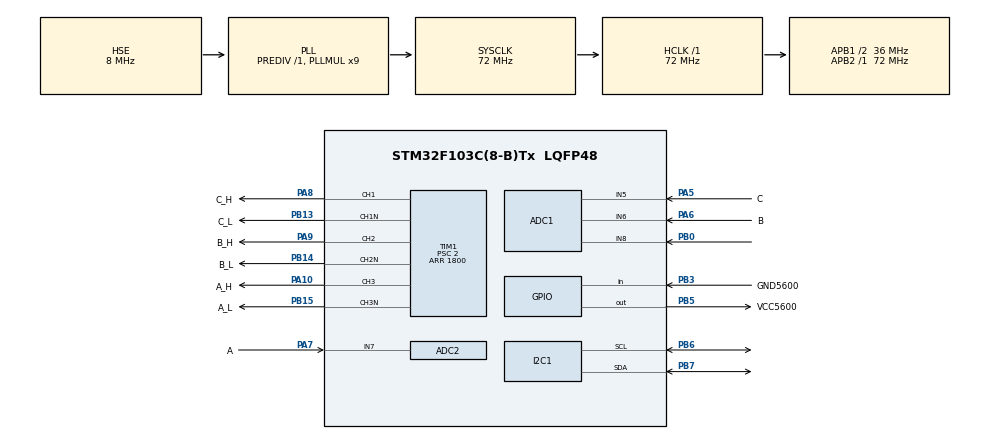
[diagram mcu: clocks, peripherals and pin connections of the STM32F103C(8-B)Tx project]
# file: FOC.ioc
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ADC1.Channel-2\#ChannelInjectedConversion=ADC_CHANNEL_5
ADC1.EnableInjectedConversion=ENABLE
ADC1.EnableRegularConversion=DISABLE
ADC1.ExternalTrigInjecConv=ADC_EXTERNALTRIGINJECCONV_T1_TRGO
ADC1.InjNumberOfConversion=1
ADC1.InjectedOffset-2\#ChannelInjectedConversion=0
ADC1.InjectedRank-2\#ChannelInjectedConversion=1
ADC1.SamplingTime-2\#ChannelInjectedConversion=ADC_SAMPLETIME_1CYCLE_5
ADC1.master=1
ADC2.Channel-1\#ChannelInjectedConversion=ADC_CHANNEL_6
ADC2.EnableInjectedConversion=ENABLE
ADC2.EnableRegularConversion=DISABLE
ADC2.ExternalTrigInjecConv=ADC_EXTERNALTRIGINJECCONV_T1_TRGO
ADC2.InjNumberOfConversion=1
ADC2.InjectedOffset-1\#ChannelInjectedConversion=0
ADC2.InjectedRank-1\#ChannelInjectedConversion=1
ADC2.SamplingTime-1\#ChannelInjectedConversion=ADC_SAMPLETIME_1CYCLE_5
Dma.I2C1_RX.0.Direction=DMA_PERIPH_TO_MEMORY
Dma.I2C1_RX.0.Instance=DMA1_Channel7
Dma.I2C1_RX.0.MemDataAlignment=DMA_MDATAALIGN_BYTE
Dma.I2C1_RX.0.MemInc=DMA_MINC_ENABLE
Dma.I2C1_RX.0.Mode=DMA_NORMAL
Dma.I2C1_RX.0.PeriphDataAlignment=DMA_PDATAALIGN_BYTE
Dma.I2C1_RX.0.PeriphInc=DMA_PINC_DISABLE
Dma.I2C1_RX.0.Priority=DMA_PRIORITY_LOW
Dma.I2C1_TX.1.Direction=DMA_MEMORY_TO_PERIPH
Dma.I2C1_TX.1.Instance=DMA1_Channel6
Dma.I2C1_TX.1.MemDataAlignment=DMA_MDATAALIGN_BYTE
Dma.I2C1_TX.1.MemInc=DMA_MINC_ENABLE
Dma.I2C1_TX.1.Mode=DMA_NORMAL
Dma.I2C1_TX.1.PeriphDataAlignment=DMA_PDATAALIGN_BYTE
Dma.I2C1_TX.1.PeriphInc=DMA_PINC_DISABLE
Dma.I2C1_TX.1.Priority=DMA_PRIORITY_LOW
Dma.Request0=I2C1_RX
Dma.Request1=I2C1_TX
I2C1.I2C_Mode=I2C_Fast
Mcu.Family=STM32F1
Mcu.Name=STM32F103C(8-B)Tx
Mcu.Package=LQFP48
NVIC.ADC1_2_IRQn=true\:0\:0\:false\:false\:true\:true\:true\:true
NVIC.DMA1_Channel6_IRQn=true\:0\:0\:false\:false\:true\:false\:true\:true
NVIC.DMA1_Channel7_IRQn=true\:0\:0\:false\:false\:true\:false\:true\:true
NVIC.I2C1_ER_IRQn=true\:0\:0\:false\:false\:true\:true\:true\:true
NVIC.I2C1_EV_IRQn=true\:0\:0\:false\:false\:true\:true\:true\:true
NVIC.PriorityGroup=NVIC_PRIORITYGROUP_4
NVIC.TIM1_UP_IRQn=true\:0\:0\:false\:false\:true\:true\:true\:true
NVIC.TIM2_IRQn=true\:0\:0\:false\:false\:true\:true\:true\:true
PA10.GPIO_Label=A_H
PA10.GPIO_ModeDefaultPP=GPIO_MODE_AF_PP
PA10.GPIO_Speed=GPIO_SPEED_FREQ_HIGH
PA10.Signal=S_TIM1_CH3
PA13.Mode=Serial_Wire
PA13.Signal=SYS_JTMS-SWDIO
PA14.Mode=Serial_Wire
PA14.Signal=SYS_JTCK-SWCLK
PA5.GPIO_Label=C
PA5.Signal=ADCx_IN5
PA6.GPIO_Label=B
PA6.Signal=ADCx_IN6
PA7.GPIO_Label=A
PA7.Signal=ADCx_IN7
PA8.GPIO_Label=C_H
PA8.GPIO_ModeDefaultPP=GPIO_MODE_AF_PP
PA8.GPIO_Speed=GPIO_SPEED_FREQ_HIGH
PA8.Signal=S_TIM1_CH1
PA9.GPIO_Label=B_H
PA9.GPIO_ModeDefaultPP=GPIO_MODE_AF_PP
PA9.GPIO_Speed=GPIO_SPEED_FREQ_HIGH
PA9.Signal=S_TIM1_CH2
PB0.Signal=ADCx_IN8
PB13.GPIO_Label=C_L
PB13.GPIO_ModeDefaultPP=GPIO_MODE_AF_PP
PB13.GPIO_Speed=GPIO_SPEED_FREQ_HIGH
PB13.Mode=PWM Generation1 CH1 CH1N
PB13.Signal=TIM1_CH1N
PB14.GPIO_Label=B_L
PB14.GPIO_ModeDefaultPP=GPIO_MODE_AF_PP
PB14.GPIO_Speed=GPIO_SPEED_FREQ_HIGH
PB14.Mode=PWM Generation2 CH2 CH2N
PB14.Signal=TIM1_CH2N
PB15.GPIO_Label=A_L
PB15.GPIO_ModeDefaultPP=GPIO_MODE_AF_PP
PB15.GPIO_Speed=GPIO_SPEED_FREQ_HIGH
PB15.Mode=PWM Generation3 CH3 CH3N
PB15.Signal=TIM1_CH3N
PB3.GPIO_Label=GND5600
PB3.GPIO_PuPd=GPIO_PULLDOWN
PB3.Signal=GPIO_Input
PB5.GPIO_Label=VCC5600
PB5.GPIO_ModeDefaultOutputPP=GPIO_MODE_OUTPUT_PP
PB5.GPIO_PuPd=GPIO_PULLUP
PB5.PinState=GPIO_PIN_SET
PB5.Signal=GPIO_Output
PB6.Mode=I2C
PB6.Signal=I2C1_SCL
PB7.Mode=I2C
PB7.Signal=I2C1_SDA
PD0-OSC_IN.Mode=HSE-External-Oscillator
PD0-OSC_IN.Signal=RCC_OSC_IN
PD1-OSC_OUT.Mode=HSE-External-Oscillator
PD1-OSC_OUT.Signal=RCC_OSC_OUT
ProjectManager.HeapSize=0x200
ProjectManager.StackSize=0x400
ProjectManager.TargetToolchain=MDK-ARM V5.32
RCC.ADCPresc=RCC_ADCPCLK2_DIV6
RCC.AHBFreq_Value=72000000
RCC.APB1CLKDivider=RCC_HCLK_DIV2
RCC.APB1Freq_Value=36000000
RCC.APB1TimFreq_Value=72000000
RCC.APB2Freq_Value=72000000
RCC.APB2TimFreq_Value=72000000
RCC.HCLKFreq_Value=72000000
RCC.PLLMUL=RCC_PLL_MUL9
RCC.PLLSourceVirtual=RCC_PLLSOURCE_HSE
RCC.SYSCLKFreq_VALUE=72000000
RCC.SYSCLKSource=RCC_SYSCLKSOURCE_PLLCLK
RCC.USBFreq_Value=72000000
SH.ADCx_IN5.0=ADC1_IN5,IN5
SH.ADCx_IN6.0=ADC1_IN6,IN6
SH.ADCx_IN6.1=ADC2_IN6,IN6
SH.ADCx_IN7.0=ADC2_IN7,IN7
SH.ADCx_IN8.0=ADC1_IN8,IN8
SH.ADCx_IN8.1=ADC2_IN8,IN8
SH.S_TIM1_CH1.0=TIM1_CH1,PWM Generation1 CH1 CH1N
SH.S_TIM1_CH2.0=TIM1_CH2,PWM Generation2 CH2 CH2N
SH.S_TIM1_CH3.0=TIM1_CH3,PWM Generation3 CH3 CH3N
TIM1.AutoReloadPreload=TIM_AUTORELOAD_PRELOAD_ENABLE
TIM1.Channel-PWM\ Generation1\ CH1\ CH1N=TIM_CHANNEL_1
TIM1.Channel-PWM\ Generation2\ CH2\ CH2N=TIM_CHANNEL_2
TIM1.Channel-PWM\ Generation3\ CH3\ CH3N=TIM_CHANNEL_3
TIM1.Channel-PWM\ Generation4\ No\ Output=TIM_CHANNEL_4
TIM1.CounterMode=TIM_COUNTERMODE_CENTERALIGNED2
TIM1.DeadTime=5
TIM1.OCMode_PWM-PWM\ Generation4\ No\ Output=TIM_OCMODE_PWM2
TIM1.Period=1800
TIM1.Prescaler=2
TIM1.Pulse-PWM\ Generation4\ No\ Output=1800-1
TIM1.TIM_MasterOutputTrigger=TIM_TRGO_OC4REF
TIM2.Channel-PWM\ Generation1\ No\ Output=TIM_CHANNEL_1
TIM2.Period=1
TIM2.Prescaler=72
VP_TIM1_VS_ClockSourceINT.Mode=Internal
VP_TIM1_VS_no_output4.Mode=PWM Generation4 No Output
VP_TIM2_VS_no_output1.Mode=PWM Generation1 No Output
board=custom

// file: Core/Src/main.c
/* USER CODE BEGIN Header */
/**
  ******************************************************************************
  * @file           : main.c
  * @brief          : Main program body
  ******************************************************************************
  * @attention
  *
  * Copyright (c) 2024 STMicroelectronics.
  * All rights reserved.
  *
  * This software is licensed under terms that can be found in the LICENSE file
  * in the root directory of this software component.
  * If no LICENSE file comes with this software, it is provided AS-IS.
  *
  ******************************************************************************
  */
/* USER CODE END Header */
#include "main.h"
#include "adc.h"
#include "dma.h"
#include "i2c.h"
#include "tim.h"
#include "gpio.h"

/* USER CODE BEGIN Includes */
#include "FOC_math.h"
/* USER CODE END Includes */

void SystemClock_Config(void);

/* USER CODE BEGIN 0 */
float current = 0.0f;
uint64_t ccr;
/* USER CODE END 0 */

int main(void)
{

  /* MCU Configuration--------------------------------------------------------*/

  /* Reset of all peripherals, Initializes the Flash interface and the Systick. */
  HAL_Init();

  /* Configure the system clock */
  SystemClock_Config();

  /* Initialize all configured peripherals */
  MX_GPIO_Init();
  MX_DMA_Init();
  MX_ADC1_Init();
  MX_ADC2_Init();
  MX_TIM1_Init();
  MX_TIM2_Init();
  MX_I2C1_Init();
  /* USER CODE BEGIN 2 */

  FOC_Init();
  /* USER CODE END 2 */

  /* Infinite loop */
  while (1)
  {

    /* USER CODE BEGIN 3 */

      FOCSetCurrent(current);
  }
  /* USER CODE END 3 */
}

void SystemClock_Config(void)
{
  RCC_OscInitTypeDef RCC_OscInitStruct = {0};
  RCC_ClkInitTypeDef RCC_ClkInitStruct = {0};
  RCC_PeriphCLKInitTypeDef PeriphClkInit = {0};

  /** Initializes the RCC Oscillators according to the specified parameters
  * in the RCC_OscInitTypeDef structure.
  */
  RCC_OscInitStruct.OscillatorType = RCC_OSCILLATORTYPE_HSE;
  RCC_OscInitStruct.HSEState = RCC_HSE_ON;
  RCC_OscInitStruct.HSEPredivValue = RCC_HSE_PREDIV_DIV1;
  RCC_OscInitStruct.HSIState = RCC_HSI_ON;
  RCC_OscInitStruct.PLL.PLLState = RCC_PLL_ON;
  RCC_OscInitStruct.PLL.PLLSource = RCC_PLLSOURCE_HSE;
  RCC_OscInitStruct.PLL.PLLMUL = RCC_PLL_MUL9;
  if (HAL_RCC_OscConfig(&RCC_OscInitStruct) != HAL_OK)
  {
    Error_Handler();
  }

  /** Initializes the CPU, AHB and APB buses clocks
  */
  RCC_ClkInitStruct.ClockType = RCC_CLOCKTYPE_HCLK|RCC_CLOCKTYPE_SYSCLK
                              |RCC_CLOCKTYPE_PCLK1|RCC_CLOCKTYPE_PCLK2;
  RCC_ClkInitStruct.SYSCLKSource = RCC_SYSCLKSOURCE_PLLCLK;
  RCC_ClkInitStruct.AHBCLKDivider = RCC_SYSCLK_DIV1;
  RCC_ClkInitStruct.APB1CLKDivider = RCC_HCLK_DIV2;
  RCC_ClkInitStruct.APB2CLKDivider = RCC_HCLK_DIV1;

  if (HAL_RCC_ClockConfig(&RCC_ClkInitStruct, FLASH_LATENCY_2) != HAL_OK)
  {
    Error_Handler();
  }
  PeriphClkInit.PeriphClockSelection = RCC_PERIPHCLK_ADC;
  PeriphClkInit.AdcClockSelection = RCC_ADCPCLK2_DIV6;
  if (HAL_RCCEx_PeriphCLKConfig(&PeriphClkInit) != HAL_OK)
  {
    Error_Handler();
  }
}

void Error_Handler(void)
{
  __disable_irq();
  while (1)
  {
  }
}
